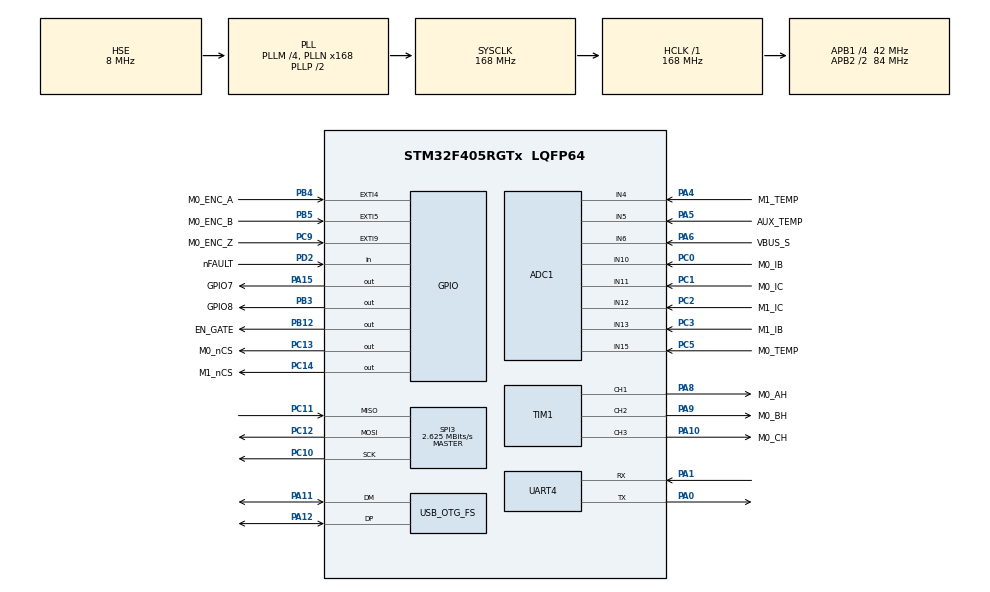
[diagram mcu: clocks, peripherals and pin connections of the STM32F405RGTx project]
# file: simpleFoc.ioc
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ADC1.Channel-0\#ChannelRegularConversion=ADC_CHANNEL_6
ADC1.Channel-1\#ChannelInjectedConversion=ADC_CHANNEL_6
ADC1.ExternalTrigInjecConv=ADC_EXTERNALTRIGINJECCONV_T1_TRGO
ADC1.InjNumberOfConversion=1
ADC1.InjectedOffset-1\#ChannelInjectedConversion=0
ADC1.InjectedRank-1\#ChannelInjectedConversion=1
ADC1.NbrOfConversionFlag=1
ADC1.Rank-0\#ChannelRegularConversion=1
ADC1.SamplingTime-0\#ChannelRegularConversion=ADC_SAMPLETIME_3CYCLES
ADC1.SamplingTime-1\#ChannelInjectedConversion=ADC_SAMPLETIME_3CYCLES
ADC1.master=1
ADC2.Channel-2\#ChannelRegularConversion=ADC_CHANNEL_13
ADC2.Channel-3\#ChannelInjectedConversion=ADC_CHANNEL_10
ADC2.ExternalTrigConv=ADC_EXTERNALTRIGCONV_T8_TRGO
ADC2.ExternalTrigInjecConv=ADC_EXTERNALTRIGINJECCONV_T1_TRGO
ADC2.InjNumberOfConversion=1
ADC2.InjectedOffset-3\#ChannelInjectedConversion=0
ADC2.InjectedRank-3\#ChannelInjectedConversion=1
ADC2.NbrOfConversionFlag=1
ADC2.Rank-2\#ChannelRegularConversion=1
ADC2.SamplingTime-2\#ChannelRegularConversion=ADC_SAMPLETIME_3CYCLES
ADC2.SamplingTime-3\#ChannelInjectedConversion=ADC_SAMPLETIME_3CYCLES
ADC3.Channel-0\#ChannelRegularConversion=ADC_CHANNEL_12
ADC3.Channel-1\#ChannelInjectedConversion=ADC_CHANNEL_11
ADC3.ExternalTrigConv=ADC_EXTERNALTRIGCONV_T8_TRGO
ADC3.ExternalTrigInjecConv=ADC_EXTERNALTRIGINJECCONV_T1_TRGO
ADC3.InjNumberOfConversion=1
ADC3.InjectedOffset-1\#ChannelInjectedConversion=0
ADC3.InjectedRank-1\#ChannelInjectedConversion=1
ADC3.NbrOfConversionFlag=1
ADC3.Rank-0\#ChannelRegularConversion=1
ADC3.SamplingTime-0\#ChannelRegularConversion=ADC_SAMPLETIME_3CYCLES
ADC3.SamplingTime-1\#ChannelInjectedConversion=ADC_SAMPLETIME_3CYCLES
Dma.ADC1.0.Direction=DMA_PERIPH_TO_MEMORY
Dma.ADC1.0.FIFOMode=DMA_FIFOMODE_DISABLE
Dma.ADC1.0.Instance=DMA2_Stream0
Dma.ADC1.0.MemDataAlignment=DMA_MDATAALIGN_HALFWORD
Dma.ADC1.0.MemInc=DMA_MINC_ENABLE
Dma.ADC1.0.Mode=DMA_CIRCULAR
Dma.ADC1.0.PeriphDataAlignment=DMA_PDATAALIGN_HALFWORD
Dma.ADC1.0.PeriphInc=DMA_PINC_DISABLE
Dma.ADC1.0.Priority=DMA_PRIORITY_LOW
Dma.Request0=ADC1
Mcu.Family=STM32F4
Mcu.Name=STM32F405RGTx
Mcu.Package=LQFP64
Mcu.UserConstants=TIM_1_8_PERIOD_CLOCKS,3500;TIM_APB1_CLOCK_HZ,84000000;TIM_APB1_PERIOD_CLOCKS,4096;TIM_1_8_RCR,1;TIM_1_8_DEADTIME_CLOCKS,20;TIM_1_8_CLOCK_HZ,168000000
NVIC.ADC_IRQn=true\:0\:0\:false\:false\:true\:true\:true\:true
NVIC.DMA2_Stream0_IRQn=true\:0\:0\:false\:false\:true\:false\:true\:true
NVIC.EXTI4_IRQn=true\:0\:0\:false\:false\:true\:true\:true\:true
NVIC.EXTI9_5_IRQn=true\:0\:0\:false\:false\:true\:true\:true\:true
NVIC.OTG_FS_IRQn=true\:0\:0\:false\:false\:true\:false\:true\:true
NVIC.PriorityGroup=NVIC_PRIORITYGROUP_4
NVIC.TIM1_UP_TIM10_IRQn=true\:0\:0\:false\:false\:true\:true\:true\:true
PA0-WKUP.Mode=Asynchronous
PA0-WKUP.Signal=UART4_TX
PA1.Mode=Asynchronous
PA1.Signal=UART4_RX
PA10.GPIO_Label=M0_CH
PA10.Signal=S_TIM1_CH3
PA11.Mode=Device_Only
PA11.Signal=USB_OTG_FS_DM
PA12.Mode=Device_Only
PA12.Signal=USB_OTG_FS_DP
PA13.Mode=Serial_Wire
PA13.Signal=SYS_JTMS-SWDIO
PA14.Mode=Serial_Wire
PA14.Signal=SYS_JTCK-SWCLK
PA15.GPIO_Label=GPIO7
PA15.Signal=GPIO_Output
PA4.GPIO_Label=M1_TEMP
PA4.Signal=ADCx_IN4
PA5.GPIO_Label=AUX_TEMP
PA5.Signal=ADCx_IN5
PA6.GPIO_Label=VBUS_S
PA6.Signal=ADCx_IN6
PA8.GPIO_Label=M0_AH
PA8.Signal=S_TIM1_CH1
PA9.GPIO_Label=M0_BH
PA9.Signal=S_TIM1_CH2
PB12.GPIO_Label=EN_GATE
PB12.Signal=GPIO_Output
PB3.GPIO_Label=GPIO8
PB3.Signal=GPIO_Output
PB4.GPIO_Label=M0_ENC_A
PB4.Signal=GPXTI4
PB5.GPIO_Label=M0_ENC_B
PB5.Signal=GPXTI5
PC0.GPIO_Label=M0_IB
PC0.Signal=ADCx_IN10
PC1.GPIO_Label=M0_IC
PC1.Signal=ADCx_IN11
PC10.Mode=Full_Duplex_Master
PC10.Signal=SPI3_SCK
PC11.Mode=Full_Duplex_Master
PC11.Signal=SPI3_MISO
PC12.Mode=Full_Duplex_Master
PC12.Signal=SPI3_MOSI
PC13-ANTI_TAMP.GPIO_Label=M0_nCS
PC13-ANTI_TAMP.PinState=GPIO_PIN_SET
PC13-ANTI_TAMP.Signal=GPIO_Output
PC14-OSC32_IN.GPIO_Label=M1_nCS
PC14-OSC32_IN.PinState=GPIO_PIN_SET
PC14-OSC32_IN.Signal=GPIO_Output
PC2.GPIO_Label=M1_IC
PC2.Signal=ADCx_IN12
PC3.GPIO_Label=M1_IB
PC3.Signal=ADCx_IN13
PC5.GPIO_Label=M0_TEMP
PC5.Signal=ADCx_IN15
PC9.GPIO_Label=M0_ENC_Z
PC9.Signal=GPXTI9
PD2.GPIO_Label=nFAULT
PD2.GPIO_PuPd=GPIO_PULLUP
PD2.Signal=GPIO_Input
PH0-OSC_IN.Mode=HSE-External-Oscillator
PH0-OSC_IN.Signal=RCC_OSC_IN
PH1-OSC_OUT.Mode=HSE-External-Oscillator
PH1-OSC_OUT.Signal=RCC_OSC_OUT
ProjectManager.HeapSize=0x200
ProjectManager.StackSize=0x400
ProjectManager.TargetToolchain=Makefile
RCC.48MHZClocksFreq_Value=48000000
RCC.AHBFreq_Value=168000000
RCC.APB1CLKDivider=RCC_HCLK_DIV4
RCC.APB1Freq_Value=42000000
RCC.APB1TimFreq_Value=84000000
RCC.APB2CLKDivider=RCC_HCLK_DIV2
RCC.APB2Freq_Value=84000000
RCC.APB2TimFreq_Value=168000000
RCC.CortexFreq_Value=168000000
RCC.HCLKFreq_Value=168000000
RCC.HSE_VALUE=8000000
RCC.HSI_VALUE=16000000
RCC.LSE_VALUE=32768
RCC.PLLM=4
RCC.PLLN=168
RCC.PLLQ=7
RCC.SYSCLKFreq_VALUE=168000000
RCC.SYSCLKSource=RCC_SYSCLKSOURCE_PLLCLK
RCC.VCOOutputFreq_Value=336000000
SH.ADCx_IN10.0=ADC1_IN10,IN10
SH.ADCx_IN10.1=ADC2_IN10,IN10
SH.ADCx_IN11.0=ADC1_IN11,IN11
SH.ADCx_IN11.1=ADC3_IN11,IN11
SH.ADCx_IN12.0=ADC1_IN12,IN12
SH.ADCx_IN12.1=ADC3_IN12,IN12
SH.ADCx_IN13.0=ADC1_IN13,IN13
SH.ADCx_IN13.1=ADC2_IN13,IN13
SH.ADCx_IN15.0=ADC1_IN15,IN15
SH.ADCx_IN4.0=ADC1_IN4,IN4
SH.ADCx_IN5.0=ADC1_IN5,IN5
SH.ADCx_IN6.0=ADC1_IN6,IN6
SH.S_TIM1_CH1.0=TIM1_CH1,PWM Generation1 CH1
SH.S_TIM1_CH2.0=TIM1_CH2,PWM Generation2 CH2
SH.S_TIM1_CH3.0=TIM1_CH3,PWM Generation3 CH3
SPI3.BaudRatePrescaler=SPI_BAUDRATEPRESCALER_16
SPI3.CLKPhase=SPI_PHASE_2EDGE
SPI3.CalculateBaudRate=2.625 MBits/s
SPI3.DataSize=SPI_DATASIZE_16BIT
SPI3.Direction=SPI_DIRECTION_2LINES
SPI3.Mode=SPI_MODE_MASTER
SPI3.VirtualType=VM_MASTER
TIM1.Channel-PWM\ Generation1\ CH1=TIM_CHANNEL_1
TIM1.Channel-PWM\ Generation2\ CH2=TIM_CHANNEL_2
TIM1.Channel-PWM\ Generation3\ CH3=TIM_CHANNEL_3
TIM1.CounterMode=TIM_COUNTERMODE_CENTERALIGNED3
TIM1.OCMode_PWM-PWM\ Generation1\ CH1=TIM_OCMODE_PWM2
TIM1.OCMode_PWM-PWM\ Generation2\ CH2=TIM_OCMODE_PWM2
TIM1.OCMode_PWM-PWM\ Generation3\ CH3=TIM_OCMODE_PWM2
TIM1.OCPolarity_1=TIM_OCPOLARITY_LOW
TIM1.OCPolarity_2=TIM_OCPOLARITY_LOW
TIM1.OCPolarity_3=TIM_OCPOLARITY_LOW
TIM1.OffStateIDLEMode=TIM_OSSI_ENABLE
TIM1.OffStateRunMode=TIM_OSSR_ENABLE
TIM1.Period=TIM_1_8_PERIOD_CLOCKS
TIM1.RepetitionCounter=TIM_1_8_RCR
TIM1.TIM_MasterOutputTrigger=TIM_TRGO_UPDATE
TIM6.Period=50000
TIM6.Prescaler=83
UART4.VirtualMode=Asynchronous
USB_DEVICE.APP_RX_DATA_SIZE-CDC_FS=64
USB_DEVICE.APP_TX_DATA_SIZE-CDC_FS=64
USB_DEVICE.CLASS_NAME_FS=CDC
USB_DEVICE.MANUFACTURER_STRING-CDC_FS=SimpleFoc
USB_DEVICE.PRODUCT_STRING_CDC_FS=SimpleFoc1.0
USB_DEVICE.VirtualMode-CDC_FS=Cdc
USB_DEVICE.VirtualModeFS=Cdc_FS
USB_OTG_FS.VirtualMode=Device_Only
VP_TIM1_VS_ClockSourceINT.Mode=Internal
VP_TIM6_VS_ClockSourceINT.Mode=Enable_Timer
VP_USB_DEVICE_VS_USB_DEVICE_CDC_FS.Mode=CDC_FS
board=custom

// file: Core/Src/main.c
/* USER CODE BEGIN Header */
/**
  ******************************************************************************
  * @file           : main.c
  * @brief          : Main program body
  ******************************************************************************
  * @attention
  *
  * Copyright (c) 2022 STMicroelectronics.
  * All rights reserved.
  *
  * This software is licensed under terms that can be found in the LICENSE file
  * in the root directory of this software component.
  * If no LICENSE file comes with this software, it is provided AS-IS.
  *
  ******************************************************************************
  */
/* USER CODE END Header */
#include "main.h"
#include "adc.h"
#include "dma.h"
#include "spi.h"
#include "tim.h"
#include "usart.h"
#include "usb_device.h"
#include "gpio.h"

/* USER CODE BEGIN Includes */
#include<stdio.h>
// #include "Print.h"
/* USER CODE END Includes */

void SystemClock_Config(void);

/* USER CODE BEGIN 0 */

int _write(int fd, char *ch, int len)
{
 HAL_UART_Transmit(&huart4, (uint8_t*)ch, len, 0xFFFF);
 return len;
}
/* USER CODE END 0 */

int main(void)
{

  /* MCU Configuration--------------------------------------------------------*/

  /* Reset of all peripherals, Initializes the Flash interface and the Systick. */
  HAL_Init();

  /* Configure the system clock */
  SystemClock_Config();

  /* Initialize all configured peripherals */
  MX_GPIO_Init();
  MX_DMA_Init();
  MX_UART4_Init();
  MX_TIM6_Init();
  MX_SPI3_Init();
  MX_ADC1_Init();
  MX_TIM1_Init();
  MX_ADC2_Init();
  MX_ADC3_Init();
  MX_USB_DEVICE_Init();
  /* USER CODE BEGIN 2 */
  printf("hello my simplefoc coming...\r\n");
  printf("SystemCoreClock = %lu\r\n",SystemCoreClock);

  /* USER CODE END 2 */

  /* Infinite loop */
  /* USER CODE BEGIN WHILE */
  // test();
  // testSimpleFOCDebug();
  DRV8301_setup();
  setup();
  while (1)
  {
    loop();
    /* USER CODE END WHILE */

  }
}

void SystemClock_Config(void)
{
  RCC_OscInitTypeDef RCC_OscInitStruct = {0};
  RCC_ClkInitTypeDef RCC_ClkInitStruct = {0};

  /** Configure the main internal regulator output voltage
  */
  __HAL_RCC_PWR_CLK_ENABLE();
  __HAL_PWR_VOLTAGESCALING_CONFIG(PWR_REGULATOR_VOLTAGE_SCALE1);

  /** Initializes the RCC Oscillators according to the specified parameters
  * in the RCC_OscInitTypeDef structure.
  */
  RCC_OscInitStruct.OscillatorType = RCC_OSCILLATORTYPE_HSE;
  RCC_OscInitStruct.HSEState = RCC_HSE_ON;
  RCC_OscInitStruct.PLL.PLLState = RCC_PLL_ON;
  RCC_OscInitStruct.PLL.PLLSource = RCC_PLLSOURCE_HSE;
  RCC_OscInitStruct.PLL.PLLM = 4;
  RCC_OscInitStruct.PLL.PLLN = 168;
  RCC_OscInitStruct.PLL.PLLP = RCC_PLLP_DIV2;
  RCC_OscInitStruct.PLL.PLLQ = 7;
  if (HAL_RCC_OscConfig(&RCC_OscInitStruct) != HAL_OK)
  {
    Error_Handler();
  }

  /** Initializes the CPU, AHB and APB buses clocks
  */
  RCC_ClkInitStruct.ClockType = RCC_CLOCKTYPE_HCLK|RCC_CLOCKTYPE_SYSCLK
                              |RCC_CLOCKTYPE_PCLK1|RCC_CLOCKTYPE_PCLK2;
  RCC_ClkInitStruct.SYSCLKSource = RCC_SYSCLKSOURCE_PLLCLK;
  RCC_ClkInitStruct.AHBCLKDivider = RCC_SYSCLK_DIV1;
  RCC_ClkInitStruct.APB1CLKDivider = RCC_HCLK_DIV4;
  RCC_ClkInitStruct.APB2CLKDivider = RCC_HCLK_DIV2;

  if (HAL_RCC_ClockConfig(&RCC_ClkInitStruct, FLASH_LATENCY_5) != HAL_OK)
  {
    Error_Handler();
  }
}

void Error_Handler(void)
{
  __disable_irq();
  while (1)
  {
  }
}
